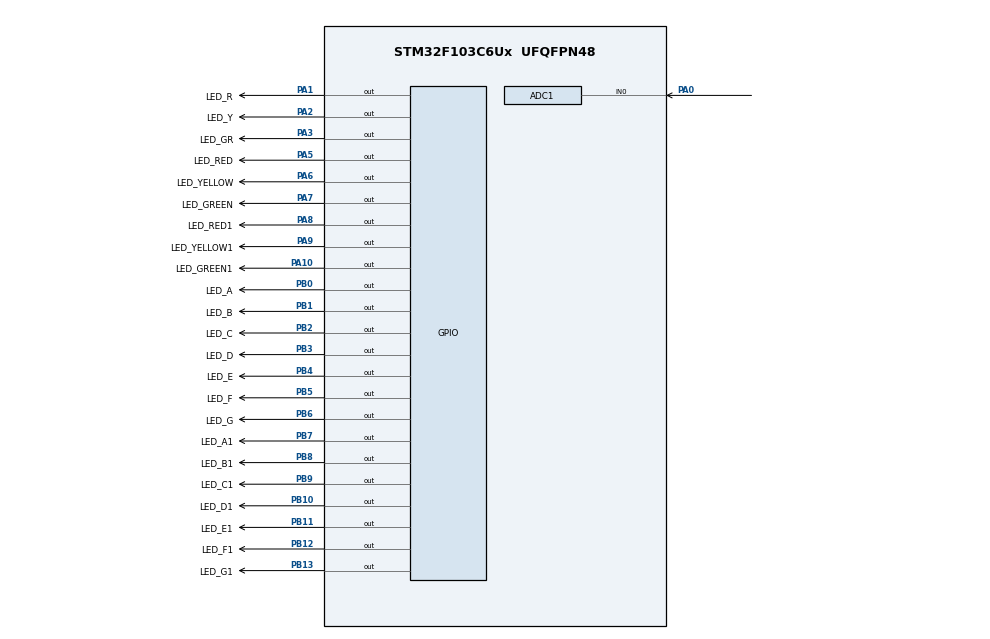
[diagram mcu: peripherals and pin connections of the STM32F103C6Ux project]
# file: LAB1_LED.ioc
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ADC1.Channel-0\#ChannelRegularConversion=ADC_CHANNEL_0
ADC1.NbrOfConversionFlag=1
ADC1.Rank-0\#ChannelRegularConversion=1
ADC1.SamplingTime-0\#ChannelRegularConversion=ADC_SAMPLETIME_1CYCLE_5
ADC1.master=1
Mcu.Family=STM32F1
Mcu.Name=STM32F103C6Ux
Mcu.Package=UFQFPN48
NVIC.PriorityGroup=NVIC_PRIORITYGROUP_4
PA0-WKUP.Signal=ADCx_IN0
PA1.GPIO_Label=LED_R
PA1.Signal=GPIO_Output
PA10.GPIO_Label=LED_GREEN1
PA10.Signal=GPIO_Output
PA2.GPIO_Label=LED_Y
PA2.Signal=GPIO_Output
PA3.GPIO_Label=LED_GR
PA3.Signal=GPIO_Output
PA5.GPIO_Label=LED_RED
PA5.Signal=GPIO_Output
PA6.GPIO_Label=LED_YELLOW
PA6.Signal=GPIO_Output
PA7.GPIO_Label=LED_GREEN
PA7.Signal=GPIO_Output
PA8.GPIO_Label=LED_RED1
PA8.Signal=GPIO_Output
PA9.GPIO_Label=LED_YELLOW1
PA9.Signal=GPIO_Output
PB0.GPIO_Label=LED_A
PB0.Signal=GPIO_Output
PB1.GPIO_Label=LED_B
PB1.Signal=GPIO_Output
PB10.GPIO_Label=LED_D1
PB10.Signal=GPIO_Output
PB11.GPIO_Label=LED_E1
PB11.Signal=GPIO_Output
PB12.GPIO_Label=LED_F1
PB12.Signal=GPIO_Output
PB13.GPIO_Label=LED_G1
PB13.Signal=GPIO_Output
PB2.GPIO_Label=LED_C
PB2.Signal=GPIO_Output
PB3.GPIO_Label=LED_D
PB3.Signal=GPIO_Output
PB4.GPIO_Label=LED_E
PB4.Signal=GPIO_Output
PB5.GPIO_Label=LED_F
PB5.Signal=GPIO_Output
PB6.GPIO_Label=LED_G
PB6.Signal=GPIO_Output
PB7.GPIO_Label=LED_A1
PB7.Signal=GPIO_Output
PB8.GPIO_Label=LED_B1
PB8.Signal=GPIO_Output
PB9.GPIO_Label=LED_C1
PB9.Signal=GPIO_Output
ProjectManager.HeapSize=0x200
ProjectManager.StackSize=0x400
ProjectManager.TargetToolchain=STM32CubeIDE
RCC.APB1Freq_Value=8000000
RCC.APB2Freq_Value=8000000
SH.ADCx_IN0.0=ADC1_IN0,IN0
VP_SYS_VS_ND.Mode=No_Debug
board=custom

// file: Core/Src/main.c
/* USER CODE BEGIN Header */
/**
  ******************************************************************************
  * @file           : main.c
  * @brief          : Main program body
  ******************************************************************************
  * @attention
  *
  * <h2><center>&copy; Copyright (c) 2024 STMicroelectronics.
  * All rights reserved.</center></h2>
  *
  * This software component is licensed by ST under BSD 3-Clause license,
  * the "License"; You may not use this file except in compliance with the
  * License. You may obtain a copy of the License at:
  *                        opensource.org/licenses/BSD-3-Clause
  *
  ******************************************************************************
  */
/* USER CODE END Header */
#include "main.h"

ADC_HandleTypeDef hadc1;

void SystemClock_Config(void);
static void MX_GPIO_Init(void);
static void MX_ADC1_Init(void);

int main(void)
{

  /* MCU Configuration--------------------------------------------------------*/

  /* Reset of all peripherals, Initializes the Flash interface and the Systick. */
  HAL_Init();

  /* Configure the system clock */
  SystemClock_Config();

  /* Initialize all configured peripherals */
  MX_GPIO_Init();
  MX_ADC1_Init();

  /* Infinite loop */
  /* USER CODE BEGIN WHILE */

  while (1)
  {
	 ex1_run();
	 HAL_Delay(1000);
    /* USER CODE END WHILE */

  }
}

void SystemClock_Config(void)
{
  RCC_OscInitTypeDef RCC_OscInitStruct = {0};
  RCC_ClkInitTypeDef RCC_ClkInitStruct = {0};
  RCC_PeriphCLKInitTypeDef PeriphClkInit = {0};

  /** Initializes the RCC Oscillators according to the specified parameters
  * in the RCC_OscInitTypeDef structure.
  */
  RCC_OscInitStruct.OscillatorType = RCC_OSCILLATORTYPE_HSI;
  RCC_OscInitStruct.HSIState = RCC_HSI_ON;
  RCC_OscInitStruct.HSICalibrationValue = RCC_HSICALIBRATION_DEFAULT;
  RCC_OscInitStruct.PLL.PLLState = RCC_PLL_NONE;
  if (HAL_RCC_OscConfig(&RCC_OscInitStruct) != HAL_OK)
  {
    Error_Handler();
  }
  /** Initializes the CPU, AHB and APB buses clocks
  */
  RCC_ClkInitStruct.ClockType = RCC_CLOCKTYPE_HCLK|RCC_CLOCKTYPE_SYSCLK
                              |RCC_CLOCKTYPE_PCLK1|RCC_CLOCKTYPE_PCLK2;
  RCC_ClkInitStruct.SYSCLKSource = RCC_SYSCLKSOURCE_HSI;
  RCC_ClkInitStruct.AHBCLKDivider = RCC_SYSCLK_DIV1;
  RCC_ClkInitStruct.APB1CLKDivider = RCC_HCLK_DIV1;
  RCC_ClkInitStruct.APB2CLKDivider = RCC_HCLK_DIV1;

  if (HAL_RCC_ClockConfig(&RCC_ClkInitStruct, FLASH_LATENCY_0) != HAL_OK)
  {
    Error_Handler();
  }
  PeriphClkInit.PeriphClockSelection = RCC_PERIPHCLK_ADC;
  PeriphClkInit.AdcClockSelection = RCC_ADCPCLK2_DIV2;
  if (HAL_RCCEx_PeriphCLKConfig(&PeriphClkInit) != HAL_OK)
  {
    Error_Handler();
  }
}

static void MX_ADC1_Init(void)
{

  ADC_ChannelConfTypeDef sConfig = {0};

  /** Common config
  */
  hadc1.Instance = ADC1;
  hadc1.Init.ScanConvMode = ADC_SCAN_DISABLE;
  hadc1.Init.ContinuousConvMode = DISABLE;
  hadc1.Init.DiscontinuousConvMode = DISABLE;
  hadc1.Init.ExternalTrigConv = ADC_SOFTWARE_START;
  hadc1.Init.DataAlign = ADC_DATAALIGN_RIGHT;
  hadc1.Init.NbrOfConversion = 1;
  if (HAL_ADC_Init(&hadc1) != HAL_OK)
  {
    Error_Handler();
  }
  /** Configure Regular Channel
  */
  sConfig.Channel = ADC_CHANNEL_0;
  sConfig.Rank = ADC_REGULAR_RANK_1;
  sConfig.SamplingTime = ADC_SAMPLETIME_1CYCLE_5;
  if (HAL_ADC_ConfigChannel(&hadc1, &sConfig) != HAL_OK)
  {
    Error_Handler();
  }

}

static void MX_GPIO_Init(void)
{
  GPIO_InitTypeDef GPIO_InitStruct = {0};

  /* GPIO Ports Clock Enable */
  __HAL_RCC_GPIOA_CLK_ENABLE();
  __HAL_RCC_GPIOB_CLK_ENABLE();

  /*Configure GPIO pin Output Level */
  HAL_GPIO_WritePin(GPIOA, LED_R_Pin|LED_Y_Pin|LED_GR_Pin|LED_RED_Pin
                          |LED_YELLOW_Pin|LED_GREEN_Pin|LED_RED1_Pin|LED_YELLOW1_Pin
                          |LED_GREEN1_Pin, GPIO_PIN_RESET);

  /*Configure GPIO pin Output Level */
  HAL_GPIO_WritePin(GPIOB, LED_A_Pin|LED_B_Pin|LED_C_Pin|LED_D1_Pin
                          |LED_E1_Pin|LED_F1_Pin|LED_G1_Pin|LED_D_Pin
                          |LED_E_Pin|LED_F_Pin|LED_G_Pin|LED_A1_Pin
                          |LED_B1_Pin|LED_C1_Pin, GPIO_PIN_RESET);

  /*Configure GPIO pins : LED_R_Pin LED_Y_Pin LED_GR_Pin LED_RED_Pin
                           LED_YELLOW_Pin LED_GREEN_Pin LED_RED1_Pin LED_YELLOW1_Pin
                           LED_GREEN1_Pin */
  GPIO_InitStruct.Pin = LED_R_Pin|LED_Y_Pin|LED_GR_Pin|LED_RED_Pin
                          |LED_YELLOW_Pin|LED_GREEN_Pin|LED_RED1_Pin|LED_YELLOW1_Pin
                          |LED_GREEN1_Pin;
  GPIO_InitStruct.Mode = GPIO_MODE_OUTPUT_PP;
  GPIO_InitStruct.Pull = GPIO_NOPULL;
  GPIO_InitStruct.Speed = GPIO_SPEED_FREQ_LOW;
  HAL_GPIO_Init(GPIOA, &GPIO_InitStruct);

  /*Configure GPIO pins : LED_A_Pin LED_B_Pin LED_C_Pin LED_D1_Pin
                           LED_E1_Pin LED_F1_Pin LED_G1_Pin LED_D_Pin
                           LED_E_Pin LED_F_Pin LED_G_Pin LED_A1_Pin
                           LED_B1_Pin LED_C1_Pin */
  GPIO_InitStruct.Pin = LED_A_Pin|LED_B_Pin|LED_C_Pin|LED_D1_Pin
                          |LED_E1_Pin|LED_F1_Pin|LED_G1_Pin|LED_D_Pin
                          |LED_E_Pin|LED_F_Pin|LED_G_Pin|LED_A1_Pin
                          |LED_B1_Pin|LED_C1_Pin;
  GPIO_InitStruct.Mode = GPIO_MODE_OUTPUT_PP;
  GPIO_InitStruct.Pull = GPIO_NOPULL;
  GPIO_InitStruct.Speed = GPIO_SPEED_FREQ_LOW;
  HAL_GPIO_Init(GPIOB, &GPIO_InitStruct);

}

void Error_Handler(void)
{
  __disable_irq();
  while (1)
  {
  }
}

/************************ (C) COPYRIGHT STMicroelectronics *****END OF FILE****/
